# j7am_pulsar1_periph_switch_cbass0_ERR register map
Vendor: Texas Instruments
Peripheral module from a debugger description file (folder J7_AHP).
Registers are 32-bit, read-only, reset 0x0 unless marked. A register's access mark holds for its fields unless they carry their own. Offsets are as the file gives them; lines under a group give offsets from that group; [hi:lo] are bit positions; {n}, {i} and the like mark numbered series; 'fields as' and 'values as' point back to an identical list; <NAME> marks a mode.

## j7am_pulsar1_periph_switch_cbass0_ERR
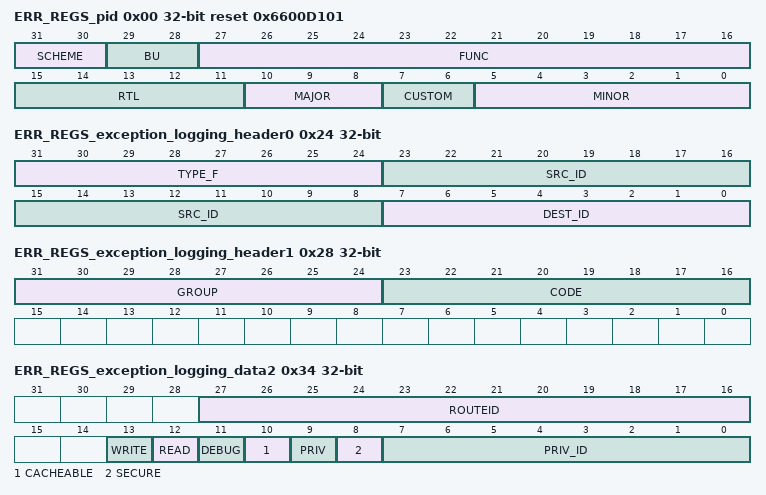
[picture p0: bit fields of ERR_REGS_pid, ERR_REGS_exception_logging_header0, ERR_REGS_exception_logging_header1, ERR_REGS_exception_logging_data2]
0x00 ERR_REGS_pid reset 0x6600D101
  [31:30] SCHEME — PID register scheme
  [29:28] BU — Business Unit: 10 = Processors
  [27:16] FUNC — Module ID
  [15:11] RTL — RTL revision. Will vary depending on release.
  [10:8] MAJOR — Major revision
  [7:6] CUSTOM
  [5:0] MINOR — Minor revision
0x04 ERR_REGS_destination_id rw
  [7:0] DEST_ID — The destination ID.
0x24 ERR_REGS_exception_logging_header0
  [31:24] TYPE_F — Type. 7 = CBASS.
  [23:8] SRC_ID — Source ID. Always 0.
  [7:0] DEST_ID — Destination ID.
0x28 ERR_REGS_exception_logging_header1
  [31:24] GROUP — Group. Always 0.
  [23:16] CODE — Code. 0 = CBASS decode error.
0x2C ERR_REGS_exception_logging_data0
  [31:0] ADDR_L — Address lower 32 bits.
0x30 ERR_REGS_exception_logging_data1
  [15:0] ADDR_H — Address upper 16 bits.
0x34 ERR_REGS_exception_logging_data2
  [27:16] ROUTEID, [13] WRITE, [12] READ, [11] DEBUG, [10] CACHEABLE, [9] PRIV, [8] SECURE, [7:0] PRIV_ID
0x38 ERR_REGS_exception_logging_data3
  [9:0] BYTECNT — Byte count.
0x50 ERR_REGS_err_intr_raw_stat access not given
  [0] INTR — Level Interrupt status (access R/W1TS)
0x54 ERR_REGS_err_intr_enabled_stat access not given
  [0] ENABLED_INTR — Level Enabled Interrupt status (access R/W1TC)
0x58 ERR_REGS_err_intr_enable_set access not given
  [0] INTR_ENABLE_SET — Interrupt Enable Set Register (access R/W1TS)
0x5C ERR_REGS_err_intr_enable_clr access not given
  [0] INTR_ENABLE_CLR — Interrupt Enable Clear Register (access R/W1TC)
0x60 ERR_REGS_err_eoi rw
  [15:0] EOI_WR — EOI Register
